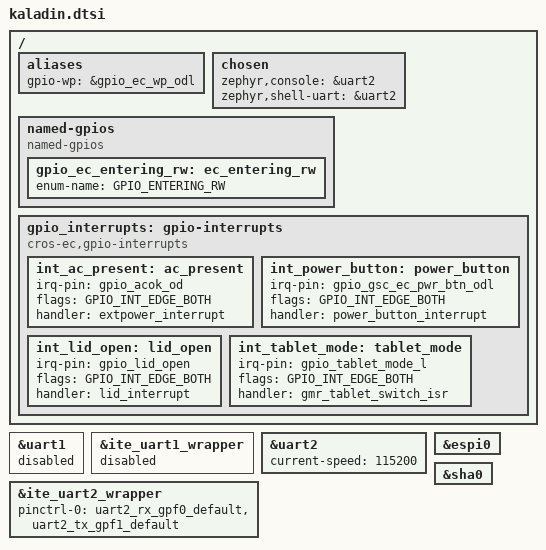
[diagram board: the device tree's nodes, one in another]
/* Copyright 2025 The ChromiumOS Authors
 * Use of this source code is governed by a BSD-style license that can be
 * found in the LICENSE file.
 */

/ {
	aliases {
		gpio-wp = &gpio_ec_wp_odl;
	};
	chosen {
		zephyr,console = &uart2;
		zephyr,shell-uart = &uart2;
	};

	named-gpios {
		compatible = "named-gpios";

		/* The legacy system code requires GPIO_ENTERING_RW symbol */
		gpio_ec_entering_rw: ec_entering_rw {
			enum-name = "GPIO_ENTERING_RW";
		};
	};

	gpio_interrupts: gpio-interrupts {
		compatible = "cros-ec,gpio-interrupts";

		int_ac_present: ac_present {
			irq-pin = <&gpio_acok_od>;
			flags = <GPIO_INT_EDGE_BOTH>;
			handler = "extpower_interrupt";
		};
		int_power_button: power_button {
			irq-pin = <&gpio_gsc_ec_pwr_btn_odl>;
			flags = <GPIO_INT_EDGE_BOTH>;
			handler = "power_button_interrupt";
		};
		int_lid_open: lid_open {
			irq-pin = <&gpio_lid_open>;
			flags = <GPIO_INT_EDGE_BOTH>;
			handler = "lid_interrupt";
		};
		int_tablet_mode: tablet_mode {
			irq-pin = <&gpio_tablet_mode_l>;
			flags = <GPIO_INT_EDGE_BOTH>;
			handler = "gmr_tablet_switch_isr";
		};
	};
};

/* UART interface is SIN1/SOUT1 pins, which ITE maps to devicetree uart2 */
&uart1 {
	status = "disabled";
};

&ite_uart1_wrapper {
	status = "disabled";
};

&uart2 {
	status = "okay";
	current-speed = <115200>;
};

&ite_uart2_wrapper {
	status = "okay";
	pinctrl-0 = <&uart2_rx_gpf0_default
		     &uart2_tx_gpf1_default>;
	pinctrl-names = "default";
};

&espi0 {
	status = "okay";
};

&sha0 {
	status = "okay";
};

